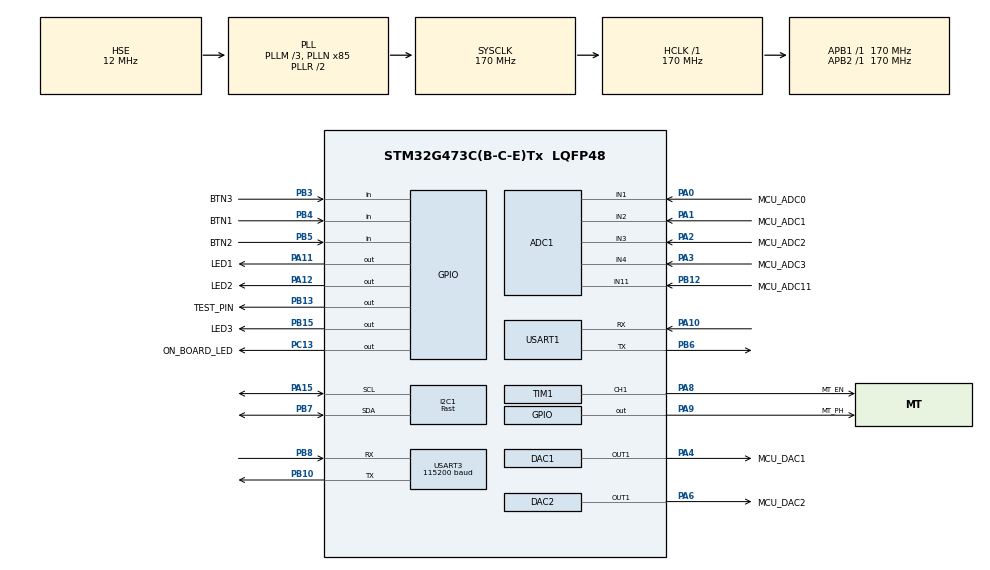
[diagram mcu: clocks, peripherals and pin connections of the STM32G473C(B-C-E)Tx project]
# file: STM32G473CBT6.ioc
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ADC1.Channel-1\#ChannelRegularConversion=ADC_CHANNEL_1
ADC1.Channel-12\#ChannelRegularConversion=ADC_CHANNEL_2
ADC1.Channel-13\#ChannelRegularConversion=ADC_CHANNEL_3
ADC1.Channel-14\#ChannelRegularConversion=ADC_CHANNEL_4
ADC1.Channel-15\#ChannelRegularConversion=ADC_CHANNEL_11
ADC1.ClockPrescaler=ADC_CLOCK_SYNC_PCLK_DIV4
ADC1.ContinuousConvMode=DISABLE
ADC1.DMAContinuousRequests=DISABLE
ADC1.EOCSelection=ADC_EOC_SINGLE_CONV
ADC1.ExternalTrigConv=ADC_EXTERNALTRIG_T8_TRGO
ADC1.NbrOfConversion=5
ADC1.NbrOfConversionFlag=1
ADC1.OffsetNumber-1\#ChannelRegularConversion=ADC_OFFSET_NONE
ADC1.OffsetNumber-12\#ChannelRegularConversion=ADC_OFFSET_NONE
ADC1.OffsetNumber-13\#ChannelRegularConversion=ADC_OFFSET_NONE
ADC1.OffsetNumber-14\#ChannelRegularConversion=ADC_OFFSET_NONE
ADC1.OffsetNumber-15\#ChannelRegularConversion=ADC_OFFSET_NONE
ADC1.OversamplingMode=ENABLE
ADC1.Rank-1\#ChannelRegularConversion=1
ADC1.Rank-12\#ChannelRegularConversion=2
ADC1.Rank-13\#ChannelRegularConversion=3
ADC1.Rank-14\#ChannelRegularConversion=4
ADC1.Rank-15\#ChannelRegularConversion=5
ADC1.Ratio=ADC_OVERSAMPLING_RATIO_8
ADC1.RightBitShift=ADC_RIGHTBITSHIFT_3
ADC1.SamplingTime-1\#ChannelRegularConversion=ADC_SAMPLETIME_92CYCLES_5
ADC1.SamplingTime-12\#ChannelRegularConversion=ADC_SAMPLETIME_92CYCLES_5
ADC1.SamplingTime-13\#ChannelRegularConversion=ADC_SAMPLETIME_92CYCLES_5
ADC1.SamplingTime-14\#ChannelRegularConversion=ADC_SAMPLETIME_92CYCLES_5
ADC1.SamplingTime-15\#ChannelRegularConversion=ADC_SAMPLETIME_92CYCLES_5
ADC1.master=1
DAC1.DAC_OutputBuffer-DAC_OUT1=DAC_OUTPUTBUFFER_ENABLE
DAC1.DAC_SampleAndHold-DAC_OUT1=DAC_SAMPLEANDHOLD_DISABLE
DAC1.DAC_Trigger_OUT1-DAC_OUT1=DAC_TRIGGER_NONE
Dma.DAC1_CH1.0.Direction=DMA_MEMORY_TO_PERIPH
Dma.DAC1_CH1.0.EventEnable=DISABLE
Dma.DAC1_CH1.0.Instance=DMA1_Channel1
Dma.DAC1_CH1.0.MemDataAlignment=DMA_MDATAALIGN_HALFWORD
Dma.DAC1_CH1.0.MemInc=DMA_MINC_ENABLE
Dma.DAC1_CH1.0.Mode=DMA_CIRCULAR
Dma.DAC1_CH1.0.PeriphDataAlignment=DMA_PDATAALIGN_WORD
Dma.DAC1_CH1.0.PeriphInc=DMA_PINC_DISABLE
Dma.DAC1_CH1.0.Polarity=HAL_DMAMUX_REQ_GEN_RISING
Dma.DAC1_CH1.0.Priority=DMA_PRIORITY_LOW
Dma.DAC1_CH1.0.RequestNumber=1
Dma.DAC1_CH1.0.SignalID=NONE
Dma.DAC1_CH1.0.SyncEnable=DISABLE
Dma.DAC1_CH1.0.SyncPolarity=HAL_DMAMUX_SYNC_NO_EVENT
Dma.DAC1_CH1.0.SyncRequestNumber=1
Dma.DAC1_CH1.0.SyncSignalID=NONE
Dma.Request0=DAC1_CH1
Dma.Request1=USART1_RX
Dma.Request2=USART3_TX
Dma.Request3=USART3_RX
Dma.USART1_RX.1.Direction=DMA_PERIPH_TO_MEMORY
Dma.USART1_RX.1.EventEnable=DISABLE
Dma.USART1_RX.1.Instance=DMA1_Channel2
Dma.USART1_RX.1.MemDataAlignment=DMA_MDATAALIGN_BYTE
Dma.USART1_RX.1.MemInc=DMA_MINC_ENABLE
Dma.USART1_RX.1.Mode=DMA_CIRCULAR
Dma.USART1_RX.1.PeriphDataAlignment=DMA_PDATAALIGN_BYTE
Dma.USART1_RX.1.PeriphInc=DMA_PINC_DISABLE
Dma.USART1_RX.1.Polarity=HAL_DMAMUX_REQ_GEN_RISING
Dma.USART1_RX.1.Priority=DMA_PRIORITY_LOW
Dma.USART1_RX.1.RequestNumber=1
Dma.USART1_RX.1.SignalID=NONE
Dma.USART1_RX.1.SyncEnable=DISABLE
Dma.USART1_RX.1.SyncPolarity=HAL_DMAMUX_SYNC_NO_EVENT
Dma.USART1_RX.1.SyncRequestNumber=1
Dma.USART1_RX.1.SyncSignalID=NONE
Dma.USART3_RX.3.Direction=DMA_PERIPH_TO_MEMORY
Dma.USART3_RX.3.EventEnable=DISABLE
Dma.USART3_RX.3.Instance=DMA1_Channel4
Dma.USART3_RX.3.MemDataAlignment=DMA_MDATAALIGN_BYTE
Dma.USART3_RX.3.MemInc=DMA_MINC_ENABLE
Dma.USART3_RX.3.Mode=DMA_CIRCULAR
Dma.USART3_RX.3.PeriphDataAlignment=DMA_PDATAALIGN_BYTE
Dma.USART3_RX.3.PeriphInc=DMA_PINC_DISABLE
Dma.USART3_RX.3.Polarity=HAL_DMAMUX_REQ_GEN_RISING
Dma.USART3_RX.3.Priority=DMA_PRIORITY_LOW
Dma.USART3_RX.3.RequestNumber=1
Dma.USART3_RX.3.SignalID=NONE
Dma.USART3_RX.3.SyncEnable=DISABLE
Dma.USART3_RX.3.SyncPolarity=HAL_DMAMUX_SYNC_NO_EVENT
Dma.USART3_RX.3.SyncRequestNumber=1
Dma.USART3_RX.3.SyncSignalID=NONE
Dma.USART3_TX.2.Direction=DMA_MEMORY_TO_PERIPH
Dma.USART3_TX.2.EventEnable=DISABLE
Dma.USART3_TX.2.Instance=DMA1_Channel3
Dma.USART3_TX.2.MemDataAlignment=DMA_MDATAALIGN_BYTE
Dma.USART3_TX.2.MemInc=DMA_MINC_ENABLE
Dma.USART3_TX.2.Mode=DMA_NORMAL
Dma.USART3_TX.2.PeriphDataAlignment=DMA_PDATAALIGN_BYTE
Dma.USART3_TX.2.PeriphInc=DMA_PINC_DISABLE
Dma.USART3_TX.2.Polarity=HAL_DMAMUX_REQ_GEN_RISING
Dma.USART3_TX.2.Priority=DMA_PRIORITY_LOW
Dma.USART3_TX.2.RequestNumber=1
Dma.USART3_TX.2.SignalID=NONE
Dma.USART3_TX.2.SyncEnable=DISABLE
Dma.USART3_TX.2.SyncPolarity=HAL_DMAMUX_SYNC_NO_EVENT
Dma.USART3_TX.2.SyncRequestNumber=1
Dma.USART3_TX.2.SyncSignalID=NONE
I2C1.I2C_Speed_Mode=I2C_Fast
I2C1.Timing=0x10802D9B
Mcu.Family=STM32G4
Mcu.Name=STM32G473C(B-C-E)Tx
Mcu.Package=LQFP48
NVIC.ADC1_2_IRQn=true\:0\:0\:false\:false\:true\:true\:true\:true
NVIC.DMA1_Channel1_IRQn=true\:0\:0\:false\:false\:true\:false\:true\:true
NVIC.DMA1_Channel2_IRQn=true\:0\:0\:false\:false\:true\:false\:true\:true
NVIC.DMA1_Channel3_IRQn=true\:0\:0\:false\:false\:true\:false\:true\:true
NVIC.DMA1_Channel4_IRQn=true\:0\:0\:false\:false\:true\:false\:true\:true
NVIC.PriorityGroup=NVIC_PRIORITYGROUP_4
NVIC.TIM1_UP_TIM16_IRQn=true\:0\:0\:false\:false\:true\:true\:true\:true
NVIC.TIM7_DAC_IRQn=true\:0\:0\:false\:false\:true\:true\:true\:true
NVIC.USART3_IRQn=true\:0\:0\:false\:false\:true\:true\:true\:true
PA0.GPIO_Label=MCU_ADC0
PA0.Mode=IN1-Single-Ended
PA0.Signal=ADC1_IN1
PA1.GPIO_Label=MCU_ADC1
PA1.Mode=IN2-Single-Ended
PA1.Signal=ADC1_IN2
PA10.Mode=Asynchronous
PA10.Signal=USART1_RX
PA11.GPIO_Label=LED1
PA11.PinState=GPIO_PIN_SET
PA11.Signal=GPIO_Output
PA12.GPIO_Label=LED2
PA12.PinState=GPIO_PIN_SET
PA12.Signal=GPIO_Output
PA13.Mode=Serial_Wire
PA13.Signal=SYS_JTMS-SWDIO
PA14.Mode=Serial_Wire
PA14.Signal=SYS_JTCK-SWCLK
PA15.GPIO_Speed=GPIO_SPEED_FREQ_VERY_HIGH
PA15.Mode=I2C
PA15.Signal=I2C1_SCL
PA2.GPIO_Label=MCU_ADC2
PA2.Mode=IN3-Single-Ended
PA2.Signal=ADC1_IN3
PA3.GPIO_Label=MCU_ADC3
PA3.Mode=IN4-Single-Ended
PA3.Signal=ADC1_IN4
PA4.GPIO_Label=MCU_DAC1
PA4.Signal=COMP_DAC11_group
PA6.GPIO_Label=MCU_DAC2
PA6.Signal=COMP_DAC21_group
PA8.GPIO_Label=MT_EN
PA8.Signal=S_TIM1_CH1
PA9.GPIO_Label=MT_PH
PA9.GPIO_Speed=GPIO_SPEED_FREQ_VERY_HIGH
PA9.Signal=GPIO_Output
PB10.GPIO_Speed=GPIO_SPEED_FREQ_VERY_HIGH
PB10.Mode=Asynchronous
PB10.Signal=USART3_TX
PB12.GPIO_Label=MCU_ADC11
PB12.Mode=IN11-Single-Ended
PB12.Signal=ADC1_IN11
PB13.GPIO_Label=TEST_PIN
PB13.GPIO_Speed=GPIO_SPEED_FREQ_MEDIUM
PB13.Signal=GPIO_Output
PB15.GPIO_Label=LED3
PB15.PinState=GPIO_PIN_SET
PB15.Signal=GPIO_Output
PB3.GPIO_Label=BTN3
PB3.GPIO_PuPd=GPIO_PULLUP
PB3.Signal=GPIO_Input
PB4.GPIO_Label=BTN1
PB4.GPIO_PuPd=GPIO_PULLUP
PB4.Signal=GPIO_Input
PB5.GPIO_Label=BTN2
PB5.GPIO_PuPd=GPIO_PULLUP
PB5.Signal=GPIO_Input
PB6.Mode=Asynchronous
PB6.Signal=USART1_TX
PB7.GPIO_FM7=SYSCFG_FASTMODEPLUS_PB7
PB7.GPIO_Speed=GPIO_SPEED_FREQ_VERY_HIGH
PB7.Mode=I2C
PB7.Signal=I2C1_SDA
PB8-BOOT0.GPIO_Speed=GPIO_SPEED_FREQ_VERY_HIGH
PB8-BOOT0.Mode=Asynchronous
PB8-BOOT0.Signal=USART3_RX
PC13.GPIO_Label=ON_BOARD_LED
PC13.PinState=GPIO_PIN_SET
PC13.Signal=GPIO_Output
PF0-OSC_IN.Mode=HSE-External-Oscillator
PF0-OSC_IN.Signal=RCC_OSC_IN
PF1-OSC_OUT.Mode=HSE-External-Oscillator
PF1-OSC_OUT.Signal=RCC_OSC_OUT
ProjectManager.HeapSize=0x200
ProjectManager.StackSize=0x400
ProjectManager.TargetToolchain=STM32CubeIDE
RCC.ADC12Freq_Value=170000000
RCC.ADC345Freq_Value=170000000
RCC.AHBFreq_Value=170000000
RCC.APB1Freq_Value=170000000
RCC.APB1TimFreq_Value=170000000
RCC.APB2Freq_Value=170000000
RCC.APB2TimFreq_Value=170000000
RCC.CortexFreq_Value=170000000
RCC.EXTERNAL_CLOCK_VALUE=12288000
RCC.HCLKFreq_Value=170000000
RCC.HSE_VALUE=12000000
RCC.HSI48_VALUE=48000000
RCC.HSI_VALUE=16000000
RCC.LSE_VALUE=32768
RCC.PLLM=RCC_PLLM_DIV3
RCC.PLLN=85
RCC.PLLSourceVirtual=RCC_PLLSOURCE_HSE
RCC.PWR_Regulator_Voltage_Scale=PWR_REGULATOR_VOLTAGE_SCALE1_BOOST
RCC.SYSCLKFreq_VALUE=170000000
RCC.SYSCLKSource=RCC_SYSCLKSOURCE_PLLCLK
RCC.USBFreq_Value=170000000
RCC.VCOOutputFreq_Value=340000000
SH.COMP_DAC11_group.0=DAC1_OUT1,DAC_OUT1
SH.COMP_DAC21_group.0=DAC2_OUT1,DAC_OUT1
SH.S_TIM1_CH1.0=TIM1_CH1,PWM Generation1 CH1
TIM1.AutoReloadPreload=TIM_AUTORELOAD_PRELOAD_ENABLE
TIM1.Channel-PWM\ Generation1\ CH1=TIM_CHANNEL_1
TIM1.CounterMode=TIM_COUNTERMODE_CENTERALIGNED1
TIM1.OCMode_PWM-PWM\ Generation1\ CH1=TIM_OCMODE_PWM1
TIM1.OCPolarity_1=TIM_OCPOLARITY_HIGH
TIM1.PeriodNoDither=8500-1
TIM1.Prescaler=1-1
TIM1.PulseNoDither_1=0
TIM1.TIM_MasterOutputTrigger=TIM_TRGO_UPDATE
TIM1.TIM_MasterOutputTrigger2=TIM_TRGO2_UPDATE
TIM6.PeriodNoDither=625-1
TIM6.Prescaler=17-1
TIM6.TIM_MasterOutputTrigger=TIM_TRGO_UPDATE
TIM7.PeriodNoDither=100-1
TIM7.Prescaler=170-1
TIM8.PeriodNoDither=100-1
TIM8.Prescaler=170-1
TIM8.TIM_MasterOutputTrigger=TIM_TRGO_UPDATE
USART1.VirtualMode-Asynchronous=VM_ASYNC
USART3.BaudRate=115200
USART3.VirtualMode-Asynchronous=VM_ASYNC
VP_SYS_VS_DBSignals.Mode=DisableDeadBatterySignals
VP_TIM1_VS_ClockSourceINT.Mode=Internal
VP_TIM6_VS_ClockSourceINT.Mode=Enable_Timer
VP_TIM7_VS_ClockSourceINT.Mode=Enable_Timer
VP_TIM8_VS_ClockSourceINT.Mode=Internal
board=custom

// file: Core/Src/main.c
/* USER CODE BEGIN Header */
/**
 ******************************************************************************
 * @file           : main.c
 * @brief          : Main program body
 ******************************************************************************
 * @attention
 *
 * Copyright (c) 2024 STMicroelectronics.
 * All rights reserved.
 *
 * This software is licensed under terms that can be found in the LICENSE file
 * in the root directory of this software component.
 * If no LICENSE file comes with this software, it is provided AS-IS.
 *
 ******************************************************************************
 */
/* USER CODE END Header */
#include "main.h"
#include "adc.h"
#include "dac.h"
#include "dma.h"
#include "i2c.h"
#include "tim.h"
#include "usart.h"
#include "gpio.h"

/* USER CODE BEGIN Includes */
#include "ap.h"
#include "control.h"
/* USER CODE END Includes */

/* USER CODE BEGIN PV */
extern TIM_HandleTypeDef htim1;
extern TIM_HandleTypeDef htim7;
extern DAC_HandleTypeDef hdac1;

/* USER CODE END PV */

void SystemClock_Config(void);

int main(void)
{

  /* MCU Configuration--------------------------------------------------------*/

  /* Reset of all peripherals, Initializes the Flash interface and the Systick. */
  HAL_Init();

  /* Configure the system clock */
  SystemClock_Config();

  /* Initialize all configured peripherals */
  MX_GPIO_Init();
  MX_DMA_Init();
  MX_DAC1_Init();
  MX_USART1_UART_Init();
  MX_TIM6_Init();
  MX_I2C1_Init();
  MX_ADC1_Init();
  MX_TIM8_Init();
  MX_USART3_UART_Init();
  MX_TIM7_Init();
  MX_DAC2_Init();
  MX_TIM1_Init();
  /* USER CODE BEGIN 2 */

  hwInit();
  apInit();

  apMain();

  /* USER CODE END 2 */

  /* Infinite loop */
  while (1)
  {

  }
}

void SystemClock_Config(void)
{
  RCC_OscInitTypeDef RCC_OscInitStruct = {0};
  RCC_ClkInitTypeDef RCC_ClkInitStruct = {0};

  /** Configure the main internal regulator output voltage
  */
  HAL_PWREx_ControlVoltageScaling(PWR_REGULATOR_VOLTAGE_SCALE1_BOOST);

  /** Initializes the RCC Oscillators according to the specified parameters
  * in the RCC_OscInitTypeDef structure.
  */
  RCC_OscInitStruct.OscillatorType = RCC_OSCILLATORTYPE_HSE;
  RCC_OscInitStruct.HSEState = RCC_HSE_ON;
  RCC_OscInitStruct.PLL.PLLState = RCC_PLL_ON;
  RCC_OscInitStruct.PLL.PLLSource = RCC_PLLSOURCE_HSE;
  RCC_OscInitStruct.PLL.PLLM = RCC_PLLM_DIV3;
  RCC_OscInitStruct.PLL.PLLN = 85;
  RCC_OscInitStruct.PLL.PLLP = RCC_PLLP_DIV2;
  RCC_OscInitStruct.PLL.PLLQ = RCC_PLLQ_DIV2;
  RCC_OscInitStruct.PLL.PLLR = RCC_PLLR_DIV2;
  if (HAL_RCC_OscConfig(&RCC_OscInitStruct) != HAL_OK)
  {
    Error_Handler();
  }

  /** Initializes the CPU, AHB and APB buses clocks
  */
  RCC_ClkInitStruct.ClockType = RCC_CLOCKTYPE_HCLK|RCC_CLOCKTYPE_SYSCLK
                              |RCC_CLOCKTYPE_PCLK1|RCC_CLOCKTYPE_PCLK2;
  RCC_ClkInitStruct.SYSCLKSource = RCC_SYSCLKSOURCE_PLLCLK;
  RCC_ClkInitStruct.AHBCLKDivider = RCC_SYSCLK_DIV1;
  RCC_ClkInitStruct.APB1CLKDivider = RCC_HCLK_DIV1;
  RCC_ClkInitStruct.APB2CLKDivider = RCC_HCLK_DIV1;

  if (HAL_RCC_ClockConfig(&RCC_ClkInitStruct, FLASH_LATENCY_4) != HAL_OK)
  {
    Error_Handler();
  }
}

void Error_Handler(void)
{
  __disable_irq();
  while (1)
  {
  }
}
